# haltium_sysctrl register map
Vendor: Nordic Semiconductor; Series: nRFHaltium; File version: 1
Registers are 32-bit, read-write, reset 0x0 unless marked. A register's access mark holds for its fields unless they carry their own. Offsets are from the block's base; [hi:lo] are bit positions; lines under a group give offsets from that group; 'fields as' and 'values as' point back to an identical list.

## FLL16M_S — FLL16M
Base 0x5F954000
0x00 TASKS_ONESHOTLOCK wo — Start one-shot locking process in Refresh mode.
  [0] TASKS_ONESHOTLOCK
    1=Trigger task
0x04 TASKS_SLEEP wo — Enter into FLL16M sleep mode
  [0] TASKS_SLEEP
    1=Trigger task
0x08 TASKS_HALT wo — Enter into FLL16M halt mode
  [0] TASKS_HALT
    1=Trigger task
0x0C TASKS_FREQMEAS wo — Start frequency measurement in software-controlled mode
  [0] TASKS_FREQMEAS
    1=Trigger task
0x100 EVENTS_FREQMDONE — Frequency measurement done
  [0] EVENTS_FREQMDONE
    0=NotGenerated (Event not generated); 1=Generated (Event generated)
0x400 READY ro — Power up status
  [0] READY — Power up ready.
    0=NotPoweredUp; 1=PoweredUp
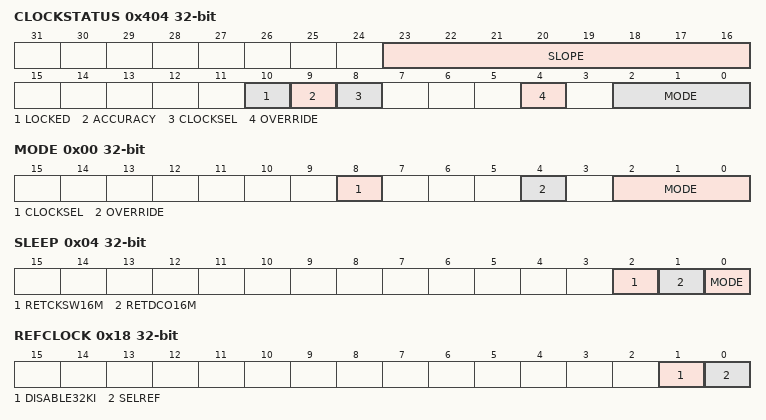
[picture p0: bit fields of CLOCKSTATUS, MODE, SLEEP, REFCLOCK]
0x404 CLOCKSTATUS ro
  [23:16] SLOPE — The calculated slope value.
  [10] LOCKED — The FLL16M lock status.
    0=Not locked to reference clock; 1=Locked to reference clock
  [9] ACCURACY — Clock accuracy.
    0=OutsideLimit (Clock accuracy is outside 2 percent.); 1=WithinLimit (Clock accuracy is within 2 percent.)
  [8] CLOCKSEL — Clock selected
    0=DCO16M (Clock from DCO16M selected.); 1=HFXO (Clock from HFXO selected.)
  [4] OVERRIDE — FLL16M Override mode.
    0=Disabled (Override mode disabled.); 1=Enabled (Override mode enabled.)
  [2:0] MODE — The FLL16M operating mode.
    0=Auto (The PCGC controls the mode automatically.); 1=Open loop mode; 2=Closed loop mode; 3=Refresh mode; 4=Bypass mode
0x408 FREQM group — Unspecified
  0x00 DONE ro — Frequency measurement done status
    [0] DONE — Measurement done.
      0=InProgress (Frequency measurement is in progress.); 1=Completed (Frequency measurement is completed.)
  0x04 ERROR ro — Frequency measurement error status
    [0] ERROR — Error status.
      1=OutsideLimit (Frequency exceeded the accuracy 0.5 percent in closed loop mode.); 0=WithinLimit (Frequency stayed within accuracy 0.5 percent in closed loop mode.)
  0x08 MEAS ro — Frequency measurement
    [10:0] VALUE — Last frequency measurement value.
  0x0C CLOCKSEL — Clock select for Frequency measurement
    [1:0] CLOCKSEL — Clock select
      0=DCO16M (Clock from DCO16M selected.); 1=CKSW16M (Clock from CKSW16M selected.); 2=HFXOBY2 (Clock from 32MHz HFXO divided by 2 selected.)
0x418 CLOCKCTRL group — Unspecified
  0x00 MODE — Clock control
    [8] CLOCKSEL — Clock select
      values as CLOCKSTATUS.CLOCKSEL
    [4] OVERRIDE — FLL16M override mode.
      values as CLOCKSTATUS.OVERRIDE
    [2:0] MODE — The FLL16M operating mode.
      values as CLOCKSTATUS.MODE
  0x04 SLEEP — Sleep configuration
    [2] RETCKSW16M — Retain CKSW16M.
      0=Disabled (No retention while powered down); 1=Enabled (Retain all inputs while powered down)
    [1] RETDCO16M — Retain DCO16M.
      values as RETCKSW16M
    [0] MODE — FLL16M sleep mode.
      0=Normal mode operation; 1=Sleep (Power down the FLL16M core)
  0x10 RETAINFINETRIM — Fine trim retain control
    [0] RETAIN — Retain control
      0=NoRetain; 1=Retain control when FLL16M goes to open-loop mode
  0x14 OVERRIDELOCKED — Override the LOCKED signal
    [0] OVERRIDE
      0=NoOperation; 1=Override
  0x18 REFCLOCK — Reference clock configuration
    [1] DISABLE32KI — Disable the 32KI reference clock
      0=Enable (The 32KI reference clock is enabled); 1=Disable (The 32KI reference clock is disabled)
    [0] SELREF — Selection for the reference clock signal in software controlled mode
      0=Clock32KI (The 32KI clock selected); 1=Clock16M (The 16MHz clock selected)
  0x1C DEFAULTSLOPE — Default slope value for FLL16M
    [8:0] VALUE — Slope value
  0x20 FREQMEASLIMIT reset 0x2 — Frequency measurement limit
    [2:0] VALUE
0x43C TRIM group — Unspecified
  0x00 CCOARSE — Coarse Cap-Trimming
    [9:0] VALUE — Cap-Trimming value.
  0x04 RCOARSE — Coarse Res-Trimming
    [4:0] VALUE — Res-Trimming value.
  0x08 RFINE — Fine frequency trimming
    [7:0] VALUE — Fine frequency trimming value.
  0x0C TCOEF — Temperature coefficient
    [7:0] VALUE
  0x10 VSUP — DCO16M internal DCO supply
    [3:0] VALUE
  0x14 CKSW16MTRIM — CKSW16M trim delay
    [3:0] VALUE
  0x18 CKSW16MREF — CKSW16M trim reference
    [6:0] VALUE
0x458 OVERRIDE group — Unspecified
  0x00 DCO16M group — Unspecified
    0x00 PWRUP — Override the PWRUP signal to the DCO16M analog module
      [31] EN — Enable the override
        0=Disabled (Override is disabled); 1=Enabled (Override is enabled)
      [0] VAL — Override value for the signal
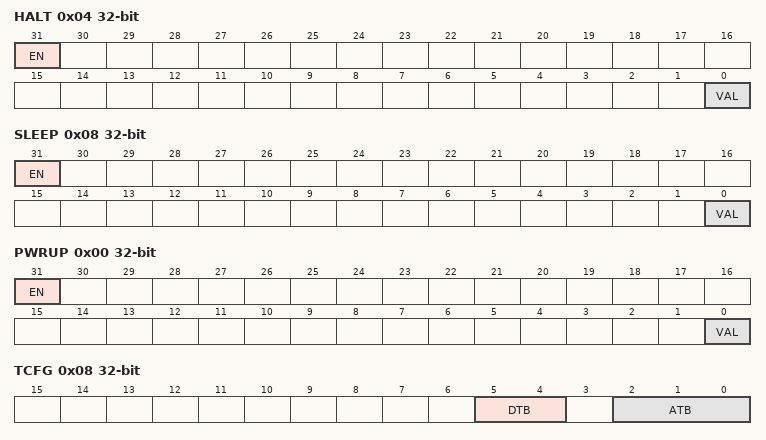
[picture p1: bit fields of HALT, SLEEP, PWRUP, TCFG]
    0x04 HALT — Override the HALT signal to the DCO16M analog module
      fields as OVERRIDE.DCO16M.PWRUP
    0x08 SLEEP — Override the SLEEP signal to the DCO16M analog module
      fields as OVERRIDE.DCO16M.PWRUP
    0x0C READY ro — Read the READY signal from the DCO16M analog module
      [0] VAL — Current value of the signal
    0x10 SETTLED ro — Read the SETTLED signal from the DCO16M analog module
      [0] VAL — Current value of the signal
  0x14 CKSW16M group — Unspecified
    0x00 PWRUP — Override the PWRUP signal to the CKSW16M analog module
      fields as OVERRIDE.DCO16M.PWRUP
    0x04 READY ro — Read the READY signal from the CKSW16M analog module
      [0] VAL — Current value of the signal
    0x08 SETTLED ro — Read the SETTLED signal from the CKSW16M analog module
      [0] VAL — Current value of the signal
0x600 DFT group — Unspecified
  0x04 DCO16M group — Unspecified
    0x00 ATE — Analog Test Bus (ATB) enable for DCO16M
      [1:0] ATB — ATB pin configuration
    0x04 DTE — Digital Test Bus (DTB) enable for DCO16M
      [3:0] DTB — DTB pin configuration.
    0x08 TCFG — Test configuration for DCO16M
      [5:4] DTB — DTB configuration
      [2:0] ATB — ATB configuration
  0x10 CKSW16M group — Unspecified
    0x00 ATE — Analog Test Bus (ATB) enable for CKSW16M
      [1:0] ATB — ATB pin configuration
    0x04 DTE — Digital Test Bus (DTB) enable for CKSW16M
      [3:0] DTB — DTB pin configuration
    0x08 TCFG — Test configuration for CKSW16M
      [5:4] DTB — DTB configuration
      [1:0] ATB — ATB configuration
